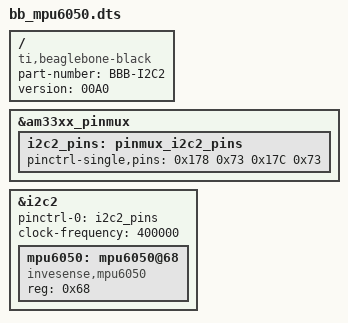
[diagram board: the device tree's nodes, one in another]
/dts-v1/;
/plugin/;

/ {
	compatible = "ti,beaglebone-black";
	part-number = "BBB-I2C2";
	version = "00A0";

	/* Adding i2c configuration */
	fragment@0 {
		target = <&am33xx_pinmux>;

		__overlay__ {
			i2c2_pins: pinmux_i2c2_pins {
				pinctrl-single,pins = <
					0x178 0x73 /*P9_20, MODE0|I2C2 SDQA*/
					0x17C 0x73 /*P9_19, MODE0|I2C2 SCL*/
				>;
			};
		};
	};

	fragment@1 {
		target = <&i2c2>;

		__overlay__ {
			pinctrl-names = "default";
			pinctrl-0 = <&i2c2_pins>;
			clock-frequency = <400000>;
			status = "okay";

			mpu6050: mpu6050@68 {
				compatible = "invesense,mpu6050";
				reg = <0x68>;
			};
		};

		
	};
};

